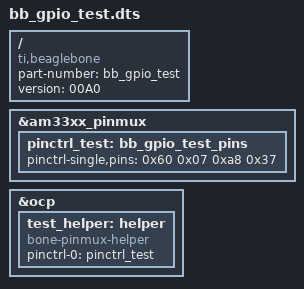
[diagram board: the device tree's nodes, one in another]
/*  
* Copyright (C) 2012 Texas Instruments Incorporated - http://www.ti.com/
*
* This program is free software; you can redistribute it and/or modify
* it under the terms of the GNU General Purpose License Version 2 as
* published by the Free Software Foundation
*
* Original from: github.com/jadonk/validation-scripts/blob/master/test-capemgr/ 
*
* Modified by Derek Molloy for the example on www.derekmolloy.ie
* that maps GPIO pins for the example
*
* Modified by John Comeau for libsoc test that doesn't require additional
* switch and LED components.
*/

/dts-v1/;
/plugin/;

/{
    compatible = "ti,beaglebone", "ti,beaglebone-black";
    part-number = "bb_gpio_test";  /* same as root of filename */
    version = "00A0";  /* apparently must be 00A0 to work with BBB */

    fragment@0 {
        target = <&am33xx_pinmux>;
        __overlay__ {
            pinctrl_test: bb_gpio_test_pins {
                pinctrl-single,pins = <
                    /* use one or the other LED, not both...
                     * USR3 if booted from SDcard, USR1 if from emmc 
                     * these are both mode 17h by default */
                    /* 0x54 0x07  /* pin 21, GPIO 53, LED USR1 */
                       0x60 0x07  /* pin 24, GPIO 56, LED USR3 */
                    /* S2, the "boot switch", mode 0 by default */
                       0xa8 0x37  /* pin 42, GPIO 72, Switch S2 */
                    /* OUTPUT  GPIO(mode7) 0x07 pulldown, 0x17 pullup,
                     *         0x?f no pullup/down */
                    /* INPUT   GPIO(mode7) 0x27 pulldown, 0x37 pullup,
                     *         0x?f no pullup/down */
                >;
            };
        };
    };

    fragment@1 {
        target = <&ocp>;
            __overlay__ {
                test_helper: helper {
                    compatible = "bone-pinmux-helper";
                    pinctrl-names = "default";
                    pinctrl-0 = <&pinctrl_test>;
                    status = "okay";
            };
        };
    };
};
